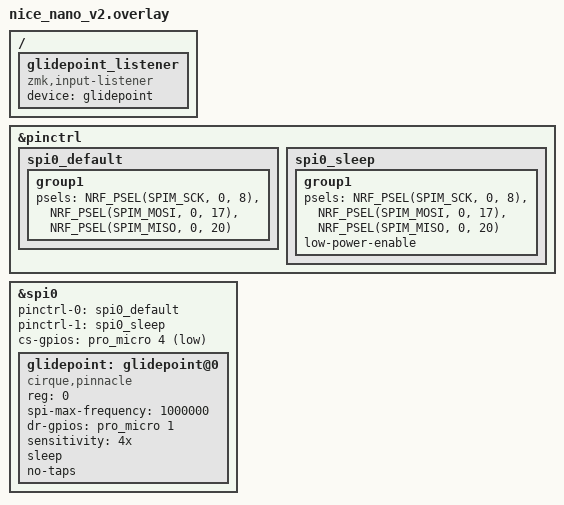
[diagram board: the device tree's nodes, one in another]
&pinctrl {
    /* configuration for spi0 device, default state */
    spi0_default: spi0_default {
        /* node name is arbitrary */
        group1 {
            /* main role: configure P0.08 (D0) as SPI clock, P0.17 (D2) as SPI MOSI, P0.20 (D3) as SPI MISO */
            psels = <NRF_PSEL(SPIM_SCK, 0, 8)>,
                    <NRF_PSEL(SPIM_MOSI, 0, 17)>,
                    <NRF_PSEL(SPIM_MISO, 0, 20)>;
        };
    };
    /* configuration for spi0 device, sleep state */
    spi0_sleep: spi0_sleep {
        group1 {
            /* main role: configure P0.08 (D0) as SPI clock, P0.17 (D2) as SPI MOSI, P0.20 (D3) as SPI MISO */
            psels = <NRF_PSEL(SPIM_SCK, 0, 8)>,
                    <NRF_PSEL(SPIM_MOSI, 0, 17)>,
                    <NRF_PSEL(SPIM_MISO, 0, 20)>;
            low-power-enable;
        };
    };
};
cirque_spi: &spi0 {
    status = "okay";
    pinctrl-0 = <&spi0_default>;
    pinctrl-1 = <&spi0_sleep>;
    pinctrl-names = "default", "sleep";
    
    cs-gpios = <&pro_micro 4 GPIO_ACTIVE_LOW>;
    glidepoint: glidepoint@0 {
        compatible = "cirque,pinnacle";
        reg = <0>;
        spi-max-frequency = <1000000>;
        status = "okay";
        dr-gpios = <&pro_micro 1 (GPIO_ACTIVE_HIGH)>;
        sensitivity = "4x";
        sleep;
        no-taps;
    };
};
/ {
    glidepoint_listener {
        compatible = "zmk,input-listener";
        device = <&glidepoint>;
    };
};
